# StarFive VisionFive 2 v1.3B register map
File version: 0.1
Registers are 32-bit, read-write, reset 0x0 unless marked. A register's access mark holds for its fields unless they carry their own. Offsets are from the block's base; [hi:lo] are bit positions; {n}, {i} and the like mark numbered series.

## sys_syscon — From starfive,jh7110-sys-syscon, peripheral generator
Base 0x13030000
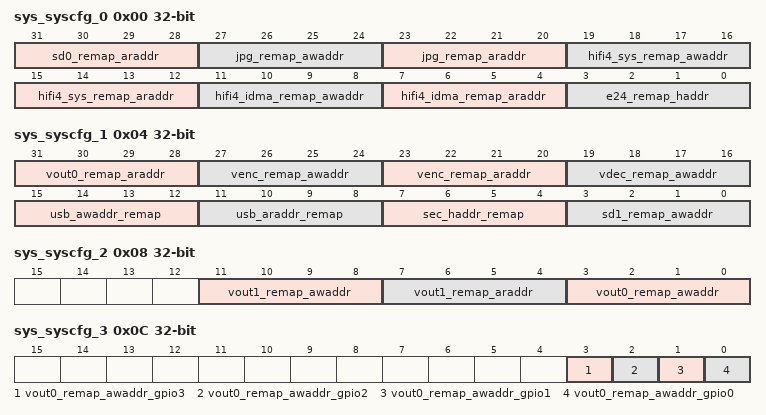
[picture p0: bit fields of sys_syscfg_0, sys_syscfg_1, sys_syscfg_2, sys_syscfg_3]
0x00 sys_syscfg_0 — SYS SYSCONSAIF SYSCFG 0
  [31:28] sd0_remap_araddr, [27:24] jpg_remap_awaddr, [23:20] jpg_remap_araddr, [19:16] hifi4_sys_remap_awaddr, [15:12] hifi4_sys_remap_araddr, [11:8] hifi4_idma_remap_awaddr, [7:4] hifi4_idma_remap_araddr, [3:0] e24_remap_haddr
0x04 sys_syscfg_1 — SYS SYSCONSAIF SYSCFG 4
  [31:28] vout0_remap_araddr, [27:24] venc_remap_awaddr, [23:20] venc_remap_araddr, [19:16] vdec_remap_awaddr, [15:12] usb_awaddr_remap, [11:8] usb_araddr_remap, [7:4] sec_haddr_remap, [3:0] sd1_remap_awaddr
0x08 sys_syscfg_2 — SYS SYSCONSAIF SYSCFG 8
  [11:8] vout1_remap_awaddr, [7:4] vout1_remap_araddr, [3:0] vout0_remap_awaddr
0x0C sys_syscfg_3 — SYS SYSCONSAIF SYSCFG 12: Set the GPIO voltage of all the 4 GPIO groups in this register
  [3] vout0_remap_awaddr_gpio3 — 0: GPIO Group 3 (GPIO7-20) voltage select 3.3V, 1: GPIO Group 3 (GPIO7-20) voltage select 1.8V
  [2] vout0_remap_awaddr_gpio2 — 0: GPIO Group 2 (GPIO0-6) voltage select 3.3V, 1: GPIO Group 2 (GPIO0-6) voltage select 1.8V
  [1] vout0_remap_awaddr_gpio1 — 0: GPIO Group 1 (GPIO36-63) voltage select 3.3V, 1: GPIO Group 1 (GPIO36-63) voltage select 1.8V
  [0] vout0_remap_awaddr_gpio0 — 0: GPIO Group 0 (GPIO21-35) voltage select 3.3V, 1: GPIO Group 0 (GPIO21-35) voltage select 1.8V
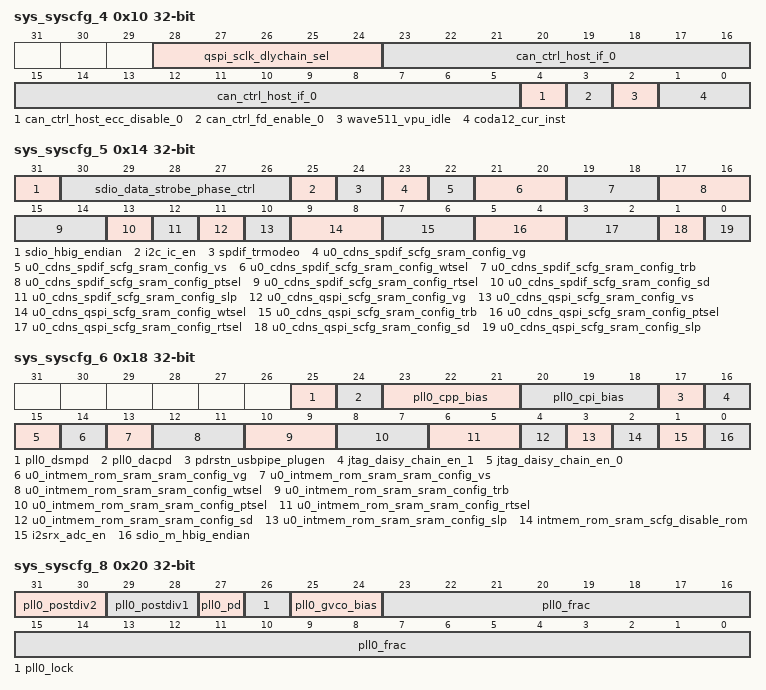
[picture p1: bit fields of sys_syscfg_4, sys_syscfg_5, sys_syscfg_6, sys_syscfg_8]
0x10 sys_syscfg_4 — SYS SYSCONSAIF SYSCFG 16
  [28:24] qspi_sclk_dlychain_sel ro — des_qspi_sclk_dla: clock delay
  [23:5] can_ctrl_host_if_0 ro
  [4] can_ctrl_host_ecc_disable_0
  [3] can_ctrl_fd_enable_0
  [2] wave511_vpu_idle ro — VPU monitoring signal
  [1:0] coda12_cur_inst ro — Tie 0 in JPU internal, do not care
0x14 sys_syscfg_5 — SYS SYSCONSAIF SYSCFG 20
  [31] sdio_hbig_endian — AHB bus interface endianness: 1: Big-endian AHB bus interface, 0: Little-endian AHB bus interface
  [30:26] sdio_data_strobe_phase_ctrl — Data strobe delay chain select
  [25] i2c_ic_en ro — I2C interface enable
  [24] spdif_trmodeo ro — 1 for transmitter 0 for receiver
  [23] u0_cdns_spdif_scfg_sram_config_vg — SRAM/ROM configuration. VG: timing setting for debug purpose, default is 1'b1.
  [22] u0_cdns_spdif_scfg_sram_config_vs — SRAM/ROM configuration. VS: timing setting for debug purpose, default is 1'b1.
  [21:20] u0_cdns_spdif_scfg_sram_config_wtsel — SRAM/ROM configuration. WTSEL: timing setting for debug purpose, default is 2'b01.
  [19:18] u0_cdns_spdif_scfg_sram_config_trb — SRAM/ROM configuration. TRB: timing setting for debug purpose, default is 2'b01.
  [17:16] u0_cdns_spdif_scfg_sram_config_ptsel — SRAM/ROM configuration. PTSEL: timing setting for debug purpose, default is 2'b01.
  [15:14] u0_cdns_spdif_scfg_sram_config_rtsel — SRAM/ROM configuration. RTSEL: timing setting for debug purpose, default is 2'b01.
  [13] u0_cdns_spdif_scfg_sram_config_sd — SRAM/ROM configuration. SD: shutdown enable, high active, default is low.
  [12] u0_cdns_spdif_scfg_sram_config_slp — SRAM/ROM configuration. SLP: sleep enable, high active, default is low.
  [11] u0_cdns_qspi_scfg_sram_config_vg — SRAM/ROM configuration. VG: timing setting for debug purpose, default is 1'b1.
  [10] u0_cdns_qspi_scfg_sram_config_vs — SRAM/ROM configuration. VS: timing setting for debug purpose, default is 1'b1.
  [9:8] u0_cdns_qspi_scfg_sram_config_wtsel — SRAM/ROM configuration. WTSEL: timing setting for debug purpose, default is 2'b01.
  [7:6] u0_cdns_qspi_scfg_sram_config_trb — SRAM/ROM configuration. TRB: timing setting for debug purpose, default is 2'b01.
  [5:4] u0_cdns_qspi_scfg_sram_config_ptsel — SRAM/ROM configuration. PTSEL: timing setting for debug purpose, default is 2'b01.
  [3:2] u0_cdns_qspi_scfg_sram_config_rtsel — SRAM/ROM configuration. RTSEL: timing setting for debug purpose, default is 2'b01.
  [1] u0_cdns_qspi_scfg_sram_config_sd — SRAM/ROM configuration. SD: shutdown enable, high active, default is low.
  [0] u0_cdns_qspi_scfg_sram_config_slp — SRAM/ROM configuration. SLP: sleep enable, high active, default is low.
0x18 sys_syscfg_6 — SYS SYSCONSAIF SYSCFG 24
  [25] pll0_dsmpd
  [24] pll0_dacpd
  [23:21] pll0_cpp_bias
  [20:18] pll0_cpi_bias
  [17] pdrstn_usbpipe_plugen
  [16] jtag_daisy_chain_en_1
  [15] jtag_daisy_chain_en_0
  [14] u0_intmem_rom_sram_sram_config_vg — SRAM/ROM configuration. VG: timing setting for debug purpose, default is 1'b1.
  [13] u0_intmem_rom_sram_sram_config_vs — SRAM/ROM configuration. VS: timing setting for debug purpose, default is 1'b1.
  [12:11] u0_intmem_rom_sram_sram_config_wtsel — SRAM/ROM configuration. WTSEL: timing setting for debug purpose, default is 2'b01.
  [10:9] u0_intmem_rom_sram_sram_config_trb — SRAM/ROM configuration. TRB: timing setting for debug purpose, default is 2'b01.
  [8:7] u0_intmem_rom_sram_sram_config_ptsel — SRAM/ROM configuration. PTSEL: timing setting for debug purpose, default is 2'b01.
  [6:5] u0_intmem_rom_sram_sram_config_rtsel — SRAM/ROM configuration. RTSEL: timing setting for debug purpose, default is 2'b01.
  [4] u0_intmem_rom_sram_sram_config_sd — SRAM/ROM configuration. SD: shutdown enable, high active, default is low.
  [3] u0_intmem_rom_sram_sram_config_slp — SRAM/ROM configuration. SLP: sleep enable, high active, default is low.
  [2] intmem_rom_sram_scfg_disable_rom
  [1] i2srx_adc_en
  [0] sdio_m_hbig_endian — AHB master bus interface endianess: 1: Big-endian AHB bus interface, 0: Little-endian AHB bus interface
0x1C sys_syscfg_7 — SYS SYSCONSAIF SYSCFG 28
  [11:0] pll0_fbdiv
0x20 sys_syscfg_8 — SYS SYSCONSAIF SYSCFG 32
  [31:30] pll0_postdiv2, [29:28] pll0_postdiv1, [27] pll0_pd, [26] pll0_lock ro, [25:24] pll0_gvco_bias, [23:0] pll0_frac
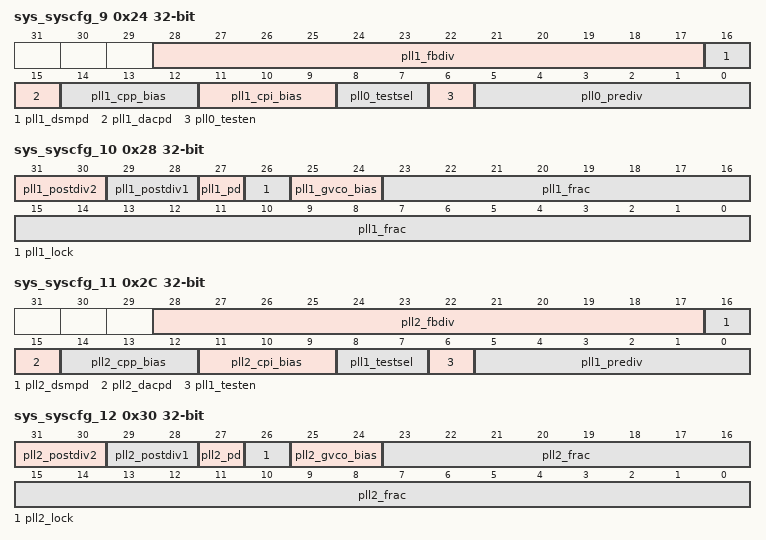
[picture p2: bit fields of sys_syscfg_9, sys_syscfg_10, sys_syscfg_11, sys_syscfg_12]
0x24 sys_syscfg_9 — SYS SYSCONSAIF SYSCFG 36
  [28:17] pll1_fbdiv, [16] pll1_dsmpd, [15] pll1_dacpd, [14:12] pll1_cpp_bias, [11:9] pll1_cpi_bias, [8:7] pll0_testsel, [6] pll0_testen, [5:0] pll0_prediv
0x28 sys_syscfg_10 — SYS SYSCONSAIF SYSCFG 40
  [31:30] pll1_postdiv2, [29:28] pll1_postdiv1, [27] pll1_pd, [26] pll1_lock ro, [25:24] pll1_gvco_bias, [23:0] pll1_frac
0x2C sys_syscfg_11 — SYS SYSCONSAIF SYSCFG 44
  [28:17] pll2_fbdiv, [16] pll2_dsmpd, [15] pll2_dacpd, [14:12] pll2_cpp_bias, [11:9] pll2_cpi_bias, [8:7] pll1_testsel, [6] pll1_testen, [5:0] pll1_prediv
0x30 sys_syscfg_12 — SYS SYSCONSAIF SYSCFG 48
  [31:30] pll2_postdiv2, [29:28] pll2_postdiv1, [27] pll2_pd, [26] pll2_lock ro, [25:24] pll2_gvco_bias, [23:0] pll2_frac
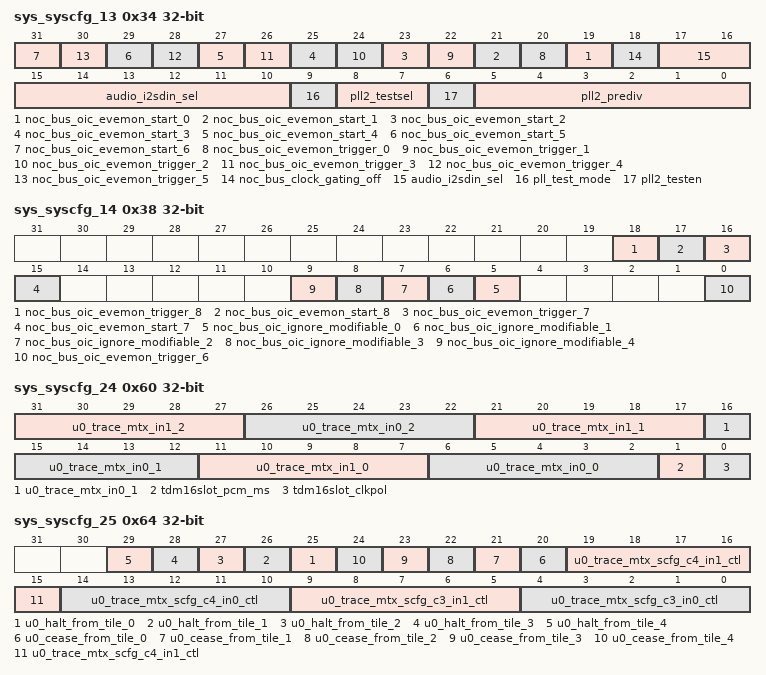
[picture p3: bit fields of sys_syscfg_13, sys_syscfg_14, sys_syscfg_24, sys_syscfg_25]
0x34 sys_syscfg_13 — SYS SYSCONSAIF SYSCFG 52
  [2n+19] noc_bus_oic_evemon_start_{n} (n=0..6)
  [2n+20] noc_bus_oic_evemon_trigger_{n} ro (n=0..5)
  [18] noc_bus_clock_gating_off
  [17:10] audio_i2sdin_sel
  [9] pll_test_mode — PLL test mode, only used for PLL BIST through jtag2apb
  [8:7] pll2_testsel
  [6] pll2_testen
  [5:0] pll2_prediv
0x38 sys_syscfg_14 — SYS SYSCONSAIF SYSCFG 56
  [18] noc_bus_oic_evemon_trigger_8 ro, [17] noc_bus_oic_evemon_start_8, [16] noc_bus_oic_evemon_trigger_7 ro, [15] noc_bus_oic_evemon_start_7, [n+5] noc_bus_oic_ignore_modifiable_{n} (n=0..4), [0] noc_bus_oic_evemon_trigger_6 ro
{0x0+4i} sys_syscfg_{i} (i=15..23) — SYS SYSCONSAIF SYSCFG {4i}
  [31:0] noc_bus_oic_qch_clock_stop_threshold_{i-15}
0x60 sys_syscfg_24 — SYS SYSCONSAIF SYSCFG 96
  [31:27] u0_trace_mtx_in1_2, [26:22] u0_trace_mtx_in0_2, [21:17] u0_trace_mtx_in1_1, [16:12] u0_trace_mtx_in0_1, [11:7] u0_trace_mtx_in1_0, [6:2] u0_trace_mtx_in0_0, [1] tdm16slot_pcm_ms ro, [0] tdm16slot_clkpol ro
0x64 sys_syscfg_25 — SYS SYSCONSAIF SYSCFG 100
  [n+25] u0_halt_from_tile_{n} ro (n=0..4), [n+20] u0_cease_from_tile_{n} ro (n=0..4), [19:15] u0_trace_mtx_scfg_c4_in1_ctl, [14:10] u0_trace_mtx_scfg_c4_in0_ctl, [9:5] u0_trace_mtx_scfg_c3_in1_ctl, [4:0] u0_trace_mtx_scfg_c3_in0_ctl
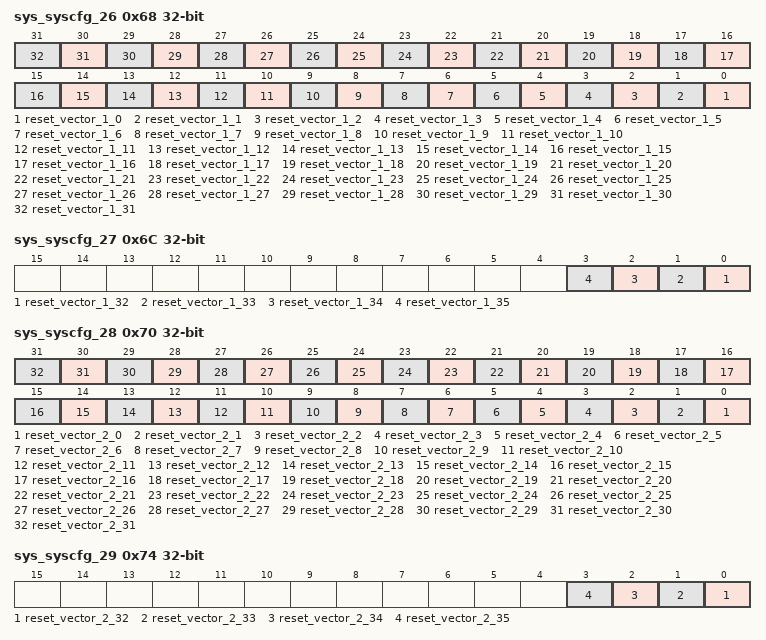
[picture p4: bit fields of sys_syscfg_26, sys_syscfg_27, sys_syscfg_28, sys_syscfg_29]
0x68 sys_syscfg_26 — SYS SYSCONSAIF SYSCFG 26
  [n] reset_vector_1_{n} (n=0..31) — U0 U74MC Reset Vector 1: {n}
0x6C sys_syscfg_27 — SYS SYSCONSAIF SYSCFG 27
  [n-32] reset_vector_1_{n} (n=32..35) — U0 U74MC Reset Vector 1: {n}
0x70 sys_syscfg_28 — SYS SYSCONSAIF SYSCFG 28
  [n] reset_vector_2_{n} (n=0..31) — U0 U74MC Reset Vector 2: {n}
0x74 sys_syscfg_29 — SYS SYSCONSAIF SYSCFG 29
  [n-32] reset_vector_2_{n} (n=32..35) — U0 U74MC Reset Vector 2: {n}
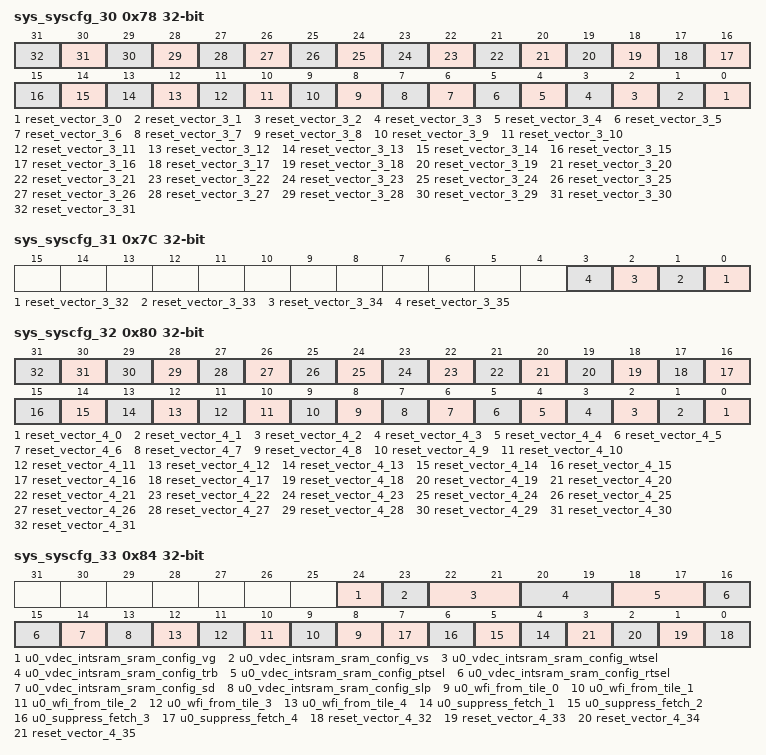
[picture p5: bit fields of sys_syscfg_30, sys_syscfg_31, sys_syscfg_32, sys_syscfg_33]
0x78 sys_syscfg_30 — SYS SYSCONSAIF SYSCFG 30
  [n] reset_vector_3_{n} (n=0..31) — U0 U74MC Reset Vector 3: {n}
0x7C sys_syscfg_31 — SYS SYSCONSAIF SYSCFG 31
  [n-32] reset_vector_3_{n} (n=32..35) — U0 U74MC Reset Vector 3: {n}
0x80 sys_syscfg_32 — SYS SYSCONSAIF SYSCFG 32
  [n] reset_vector_4_{n} (n=0..31) — U0 U74MC Reset Vector 4: {n}
0x84 sys_syscfg_33 — SYS SYSCONSAIF SYSCFG 132
  [24] u0_vdec_intsram_sram_config_vg — SRAM/ROM configuration. VG: timing setting for debug purpose, default is 1'b1.
  [23] u0_vdec_intsram_sram_config_vs — SRAM/ROM configuration. VS: timing setting for debug purpose, default is 1'b1.
  [22:21] u0_vdec_intsram_sram_config_wtsel — SRAM/ROM configuration. WTSEL: timing setting for debug purpose, default is 2'b01.
  [20:19] u0_vdec_intsram_sram_config_trb — SRAM/ROM configuration. TRB: timing setting for debug purpose, default is 2'b01.
  [18:17] u0_vdec_intsram_sram_config_ptsel — SRAM/ROM configuration. PTSEL: timing setting for debug purpose, default is 2'b01.
  [16:15] u0_vdec_intsram_sram_config_rtsel — SRAM/ROM configuration. RTSEL: timing setting for debug purpose, default is 2'b01.
  [14] u0_vdec_intsram_sram_config_sd — SRAM/ROM configuration. SD: shutdown enable, high active, default is low.
  [13] u0_vdec_intsram_sram_config_slp — SRAM/ROM configuration. SLP: sleep enable, high active, default is low.
  [n+8] u0_wfi_from_tile_{n} (n=0..4)
  [n+3] u0_suppress_fetch_{n} (n=1..4)
  [n-32] reset_vector_4_{n} (n=32..35) — U0 U74MC Reset Vector 4: {n}
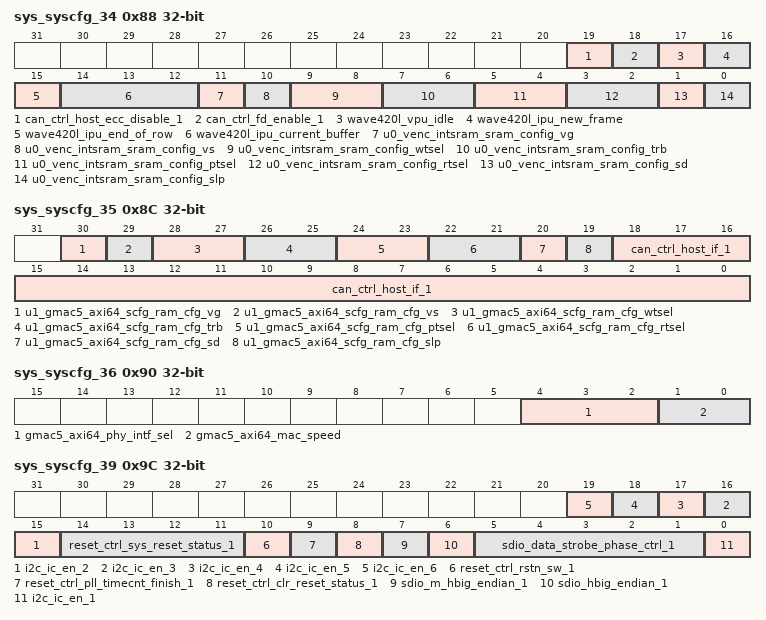
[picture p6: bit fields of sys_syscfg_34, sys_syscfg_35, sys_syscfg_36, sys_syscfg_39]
0x88 sys_syscfg_34 — SYS SYSCONSAIF SYSCFG 136
  [19] can_ctrl_host_ecc_disable_1
  [18] can_ctrl_fd_enable_1
  [17] wave420l_vpu_idle ro — VPU monitoring signal. This signal gives out an opposite value of VPU_BUSY register.
  [16] wave420l_ipu_new_frame — This signal is flipped every time when the IPU completes writing a new frame.
  [15] wave420l_ipu_end_of_row — This signal is flipped every time when the IPU completes writing a row.
  [14:12] wave420l_ipu_current_buffer — This signal indicates which buffer is currently active so that the VPU can correctly use the ipu_end_of_row signal for row counter.
  [11] u0_venc_intsram_sram_config_vg — SRAM/ROM configuration. VG: timing setting for debug purpose, default is 1'b1.
  [10] u0_venc_intsram_sram_config_vs — SRAM/ROM configuration. VS: timing setting for debug purpose, default is 1'b1.
  [9:8] u0_venc_intsram_sram_config_wtsel — SRAM/ROM configuration. WTSEL: timing setting for debug purpose, default is 2'b01.
  [7:6] u0_venc_intsram_sram_config_trb — SRAM/ROM configuration. TRB: timing setting for debug purpose, default is 2'b01.
  [5:4] u0_venc_intsram_sram_config_ptsel — SRAM/ROM configuration. PTSEL: timing setting for debug purpose, default is 2'b01.
  [3:2] u0_venc_intsram_sram_config_rtsel — SRAM/ROM configuration. RTSEL: timing setting for debug purpose, default is 2'b01.
  [1] u0_venc_intsram_sram_config_sd — SRAM/ROM configuration. SD: shutdown enable, high active, default is low.
  [0] u0_venc_intsram_sram_config_slp — SRAM/ROM configuration. SLP: sleep enable, high active, default is low.
0x8C sys_syscfg_35 — SYS SYSCONSAIF SYSCFG 140
  [30] u1_gmac5_axi64_scfg_ram_cfg_vg — SRAM/ROM configuration. VG: timing setting for debug purpose, default is 1'b1.
  [29] u1_gmac5_axi64_scfg_ram_cfg_vs — SRAM/ROM configuration. VS: timing setting for debug purpose, default is 1'b1.
  [28:27] u1_gmac5_axi64_scfg_ram_cfg_wtsel — SRAM/ROM configuration. WTSEL: timing setting for debug purpose, default is 2'b01.
  [26:25] u1_gmac5_axi64_scfg_ram_cfg_trb — SRAM/ROM configuration. TRB: timing setting for debug purpose, default is 2'b01.
  [24:23] u1_gmac5_axi64_scfg_ram_cfg_ptsel — SRAM/ROM configuration. PTSEL: timing setting for debug purpose, default is 2'b01.
  [22:21] u1_gmac5_axi64_scfg_ram_cfg_rtsel — SRAM/ROM configuration. RTSEL: timing setting for debug purpose, default is 2'b01.
  [20] u1_gmac5_axi64_scfg_ram_cfg_sd — SRAM/ROM configuration. SD: shutdown enable, high active, default is low.
  [19] u1_gmac5_axi64_scfg_ram_cfg_slp — SRAM/ROM configuration. SLP: sleep enable, high active, default is low.
  [18:0] can_ctrl_host_if_1 ro
0x90 sys_syscfg_36 — SYS SYSCONSAIF SYSCFG 144
  [4:2] gmac5_axi64_phy_intf_sel — Active PHY Selected | When you have multiple GMAC PHY interfaces in your configuration, this field indicates the sampled value of the PHY selector during reset de-assertion. | Values: 0x0:(GMII or MII), 0x01:RGMII, 0x2:SGMII, 0x3:TBI, 0x4:RMII, 0x5:RTBI, 0x6:SMII, 0x7:REVMII
  [1:0] gmac5_axi64_mac_speed ro
0x94 sys_syscfg_37 — SYS SYSCONSAIF SYSCFG 148
  [31:0] gmac5_axi64_ptp_timestamp_0_31 ro
0x98 sys_syscfg_38 — SYS SYSCONSAIF SYSCFG 152
  [31:0] gmac5_axi64_ptp_timestamp_32_63 ro
0x9C sys_syscfg_39 — SYS SYSCONSAIF SYSCFG 156
  [n+13] i2c_ic_en_{n} ro (n=2..6) — I2C interface enable.
  [14:11] reset_ctrl_sys_reset_status_1 ro
  [10] reset_ctrl_rstn_sw_1
  [9] reset_ctrl_pll_timecnt_finish_1 ro
  [8] reset_ctrl_clr_reset_status_1
  [7] sdio_m_hbig_endian_1 — AHB bus interface endianness: 1: Big-endian AHB bus interface, 0: Little-endian AHB bus interface
  [6] sdio_hbig_endian_1 — AHB bus interface endianness: 1: Big-endian AHB bus interface, 0: Little-endian AHB bus interface
  [5:1] sdio_data_strobe_phase_ctrl_1 — Data strobe delay chain select.
  [0] i2c_ic_en_1 ro — I2C interface enable.
